# STM32WB55x register map
File version: 1.0
CPU: CM4 r0p1, little endian, 4 interrupt priority bits
Registers are 32-bit, read-write, reset 0x0 unless marked. A register's access mark holds for its fields unless they carry their own. Offsets are from the block's base; [hi:lo] are bit positions; {n}, {i} and the like mark numbered series.

## SYSCFG2
Base 0x40010000
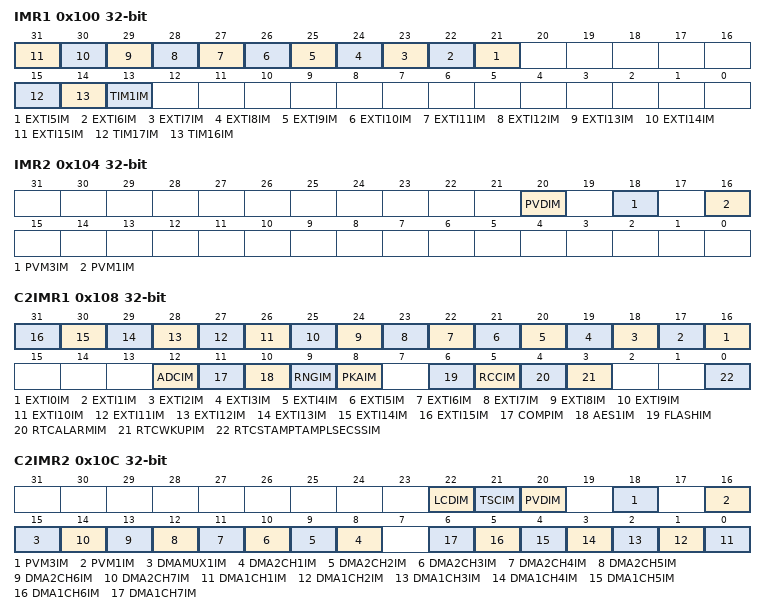
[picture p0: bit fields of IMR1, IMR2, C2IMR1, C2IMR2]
0x100 IMR1
  [n+16] EXTI{n}IM (n=5..15), [15] TIM17IM, [14] TIM16IM, [13] TIM1IM
0x104 IMR2
  [20] PVDIM, [18] PVM3IM, [16] PVM1IM
0x108 C2IMR1
  [n+16] EXTI{n}IM (n=0..15), [12] ADCIM, [11] COMPIM, [10] AES1IM, [9] RNGIM, [8] PKAIM, [6] FLASHIM, [5] RCCIM, [4] RTCALARMIM, [3] RTCWKUPIM, [0] RTCSTAMPTAMPLSECSSIM
0x10C C2IMR2
  [22] LCDIM, [21] TSCIM, [20] PVDIM, [18] PVM3IM, [16] PVM1IM, [15] DMAMUX1IM, [n+7] DMA2CH{n}IM (n=1..7), [n-1] DMA1CH{n}IM (n=1..7)
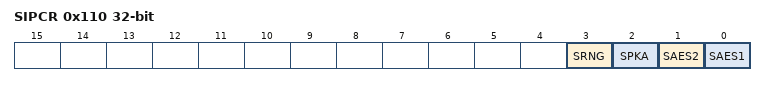
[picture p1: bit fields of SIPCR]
0x110 SIPCR
  [3] SRNG, [2] SPKA, [1] SAES2, [0] SAES1

## VREFBUF
Base 0x40010030
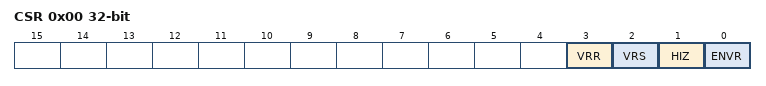
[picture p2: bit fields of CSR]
0x00 CSR
  [3] VRR, [2] VRS, [1] HIZ, [0] ENVR
0x04 CCR
  [5:0] TRIM

## IPCC
Base 0x58000C00
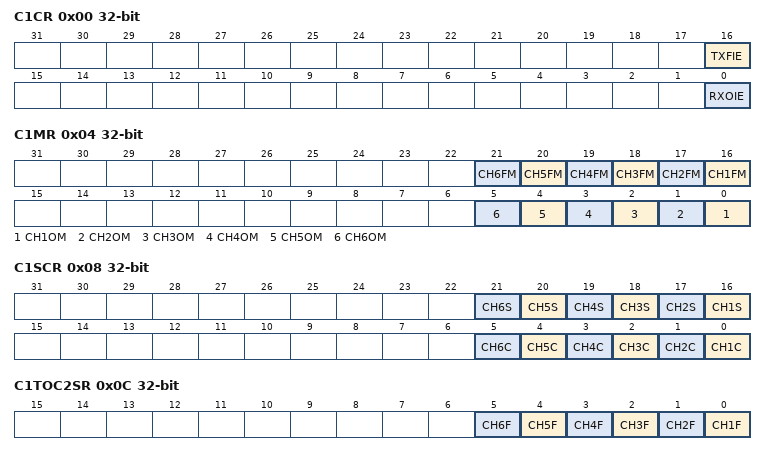
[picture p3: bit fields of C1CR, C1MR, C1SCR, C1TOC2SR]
0x00 C1CR
  [16] TXFIE, [0] RXOIE
0x04 C1MR
  [n+15] CH{n}FM (n=1..6), [n-1] CH{n}OM (n=1..6)
0x08 C1SCR
  [n+15] CH{n}S (n=1..6), [n-1] CH{n}C (n=1..6)
0x0C C1TOC2SR
  [n-1] CH{n}F (n=1..6)
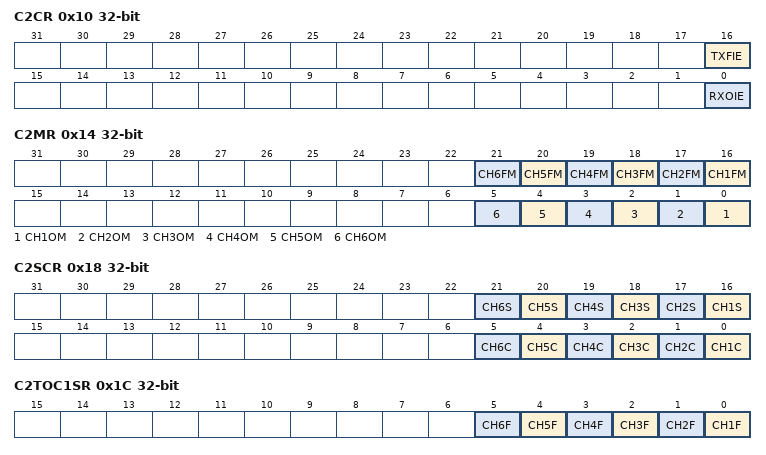
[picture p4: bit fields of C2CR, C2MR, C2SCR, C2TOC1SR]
0x10 C2CR
  [16] TXFIE, [0] RXOIE
0x14 C2MR
  [n+15] CH{n}FM (n=1..6), [n-1] CH{n}OM (n=1..6)
0x18 C2SCR
  [n+15] CH{n}S (n=1..6), [n-1] CH{n}C (n=1..6)
0x1C C2TOC1SR
  [n-1] CH{n}F (n=1..6)

## IWDG
Base 0x40003000
0x00 KR
  [15:0] KEY
0x04 PR
  [2:0] PR
0x08 RLR
  [11:0] RL
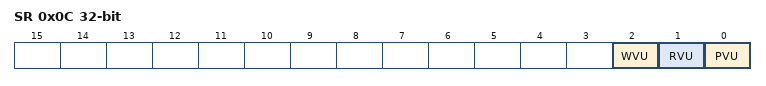
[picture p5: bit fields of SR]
0x0C SR
  [2] WVU, [1] RVU, [0] PVU
0x10 WINR
  [11:0] WIN

## WWDG
Base 0x40002C00
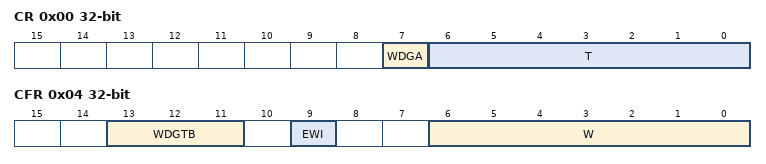
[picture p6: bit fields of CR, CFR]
0x00 CR
  [7] WDGA, [6:0] T
0x04 CFR
  [13:11] WDGTB, [9] EWI, [6:0] W
0x08 SR
  [0] EWIF

## USB_FS
Base 0x40006800
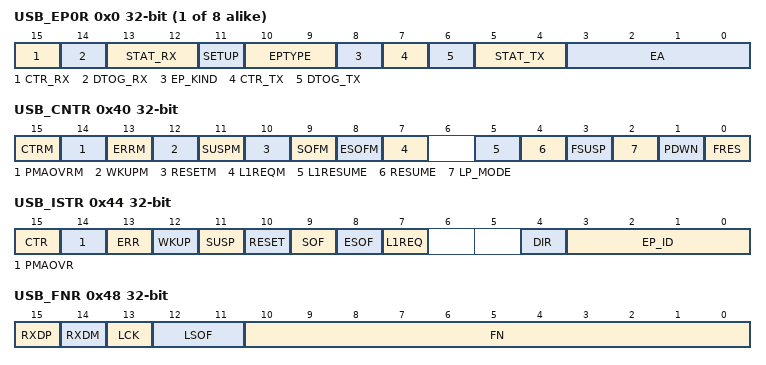
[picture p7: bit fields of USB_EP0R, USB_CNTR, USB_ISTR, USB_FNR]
{0x0+4i} USB_EP{i}R (i=0..7)
  [15] CTR_RX, [14] DTOG_RX, [13:12] STAT_RX, [11] SETUP, [10:9] EPTYPE, [8] EP_KIND, [7] CTR_TX, [6] DTOG_TX, [5:4] STAT_TX, [3:0] EA
0x40 USB_CNTR
  [15] CTRM, [14] PMAOVRM, [13] ERRM, [12] WKUPM, [11] SUSPM, [10] RESETM, [9] SOFM, [8] ESOFM, [7] L1REQM, [5] L1RESUME, [4] RESUME, [3] FSUSP, [2] LP_MODE, [1] PDWN, [0] FRES
0x44 USB_ISTR
  [15] CTR, [14] PMAOVR, [13] ERR, [12] WKUP, [11] SUSP, [10] RESET, [9] SOF, [8] ESOF, [7] L1REQ, [4] DIR, [3:0] EP_ID
0x48 USB_FNR
  [15] RXDP, [14] RXDM, [13] LCK, [12:11] LSOF, [10:0] FN
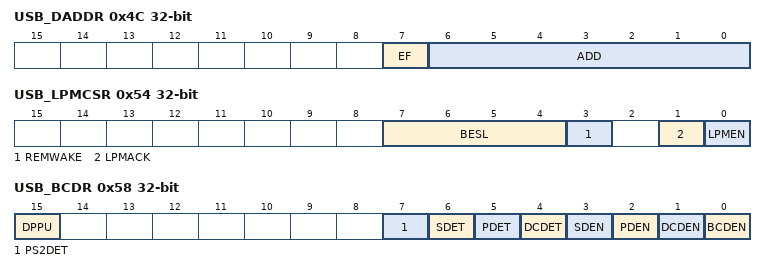
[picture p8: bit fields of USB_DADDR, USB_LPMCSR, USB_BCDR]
0x4C USB_DADDR
  [7] EF, [6:0] ADD
0x50 USB_BTABLE
  [15:3] BTABLE
0x54 USB_LPMCSR
  [7:4] BESL, [3] REMWAKE, [1] LPMACK, [0] LPMEN
0x58 USB_BCDR
  [15] DPPU, [7] PS2DET, [6] SDET, [5] PDET, [4] DCDET, [3] SDEN, [2] PDEN, [1] DCDEN, [0] BCDEN

## USART1
Base 0x40013800
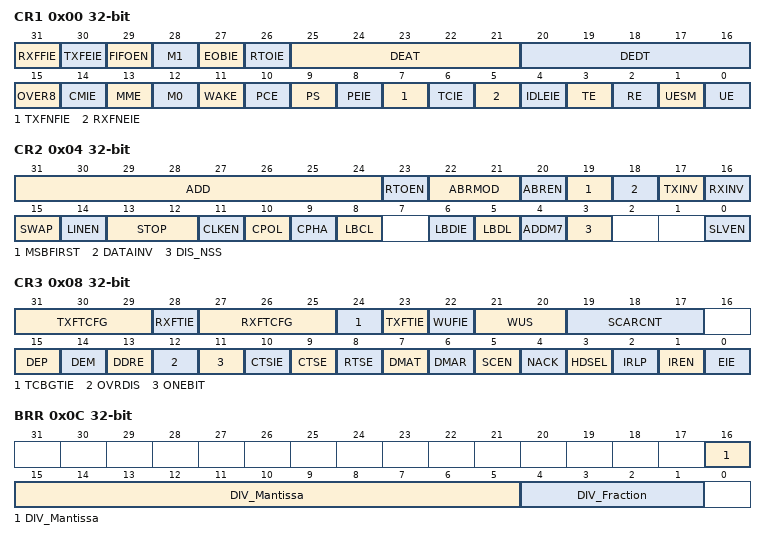
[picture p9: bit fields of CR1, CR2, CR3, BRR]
0x00 CR1
  [31] RXFFIE, [30] TXFEIE, [29] FIFOEN, [28] M1, [27] EOBIE, [26] RTOIE, [25:21] DEAT, [20:16] DEDT, [15] OVER8, [14] CMIE, [13] MME, [12] M0, [11] WAKE, [10] PCE, [9] PS, [8] PEIE, [7] TXFNFIE, [6] TCIE, [5] RXFNEIE, [4] IDLEIE, [3] TE, [2] RE, [1] UESM, [0] UE
0x04 CR2
  [31:24] ADD, [23] RTOEN, [22:21] ABRMOD, [20] ABREN, [19] MSBFIRST, [18] DATAINV, [17] TXINV, [16] RXINV, [15] SWAP, [14] LINEN, [13:12] STOP, [11] CLKEN, [10] CPOL, [9] CPHA, [8] LBCL, [6] LBDIE, [5] LBDL, [4] ADDM7, [3] DIS_NSS, [0] SLVEN
0x08 CR3
  [31:29] TXFTCFG, [28] RXFTIE, [27:25] RXFTCFG, [24] TCBGTIE, [23] TXFTIE, [22] WUFIE, [21:20] WUS, [19:17] SCARCNT, [15] DEP, [14] DEM, [13] DDRE, [12] OVRDIS, [11] ONEBIT, [10] CTSIE, [9] CTSE, [8] RTSE, [7] DMAT, [6] DMAR, [5] SCEN, [4] NACK, [3] HDSEL, [2] IRLP, [1] IREN, [0] EIE
0x0C BRR
  [16:5] DIV_Mantissa, [4:1] DIV_Fraction
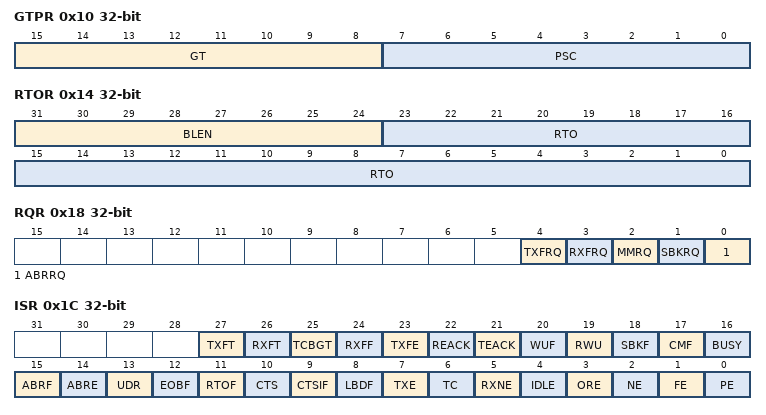
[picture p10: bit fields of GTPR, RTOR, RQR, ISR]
0x10 GTPR
  [15:8] GT, [7:0] PSC
0x14 RTOR
  [31:24] BLEN, [23:0] RTO
0x18 RQR
  [4] TXFRQ, [3] RXFRQ, [2] MMRQ, [1] SBKRQ, [0] ABRRQ
0x1C ISR
  [27] TXFT, [26] RXFT, [25] TCBGT, [24] RXFF, [23] TXFE, [22] REACK, [21] TEACK, [20] WUF, [19] RWU, [18] SBKF, [17] CMF, [16] BUSY, [15] ABRF, [14] ABRE, [13] UDR, [12] EOBF, [11] RTOF, [10] CTS, [9] CTSIF, [8] LBDF, [7] TXE, [6] TC, [5] RXNE, [4] IDLE, [3] ORE, [2] NE, [1] FE, [0] PE
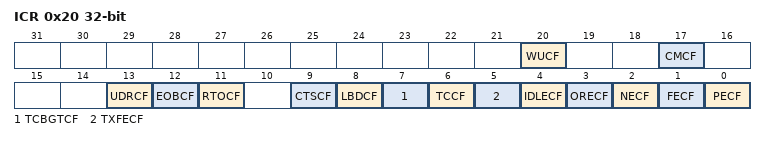
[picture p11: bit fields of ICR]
0x20 ICR
  [20] WUCF, [17] CMCF, [13] UDRCF, [12] EOBCF, [11] RTOCF, [9] CTSCF, [8] LBDCF, [7] TCBGTCF, [6] TCCF, [5] TXFECF, [4] IDLECF, [3] ORECF, [2] NECF, [1] FECF, [0] PECF
0x24 RDR
  [8:0] RDR
0x28 TDR
  [8:0] TDR
0x2C PRESC
  [3:0] PRESCALER
